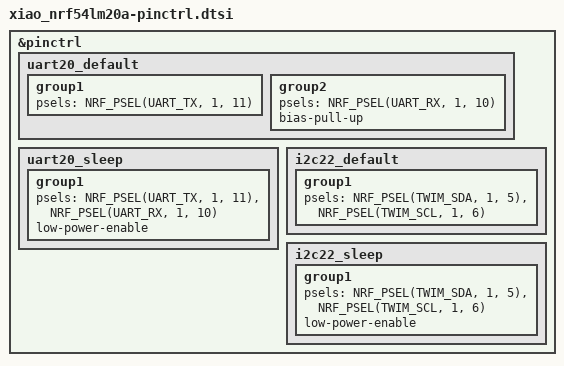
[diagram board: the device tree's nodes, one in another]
/*
 * SPDX-License-Identifier: Apache-2.0
 *
 * Pin control for the XIAO nRF54LM20A Sense. Pins verified against schematic
 * Rev V1.0 (see docs/nrf54lm20a-board.md). Only the M1 buses are defined here
 * (console UART + OLED header I2C); sensor/mic/PMIC buses are added at M3.
 */

&pinctrl {
	/* Console UART -> ATSAMD11 bridge -> USB serial. TX P1.11, RX P1.10. */
	uart20_default: uart20_default {
		group1 {
			psels = <NRF_PSEL(UART_TX, 1, 11)>;
		};
		group2 {
			psels = <NRF_PSEL(UART_RX, 1, 10)>;
			bias-pull-up;
		};
	};

	uart20_sleep: uart20_sleep {
		group1 {
			psels = <NRF_PSEL(UART_TX, 1, 11)>,
				<NRF_PSEL(UART_RX, 1, 10)>;
			low-power-enable;
		};
	};

	/*
	 * OLED bus on the XIAO header, mapped for NEAT SINGLE-EDGE WIRING.
	 * The right edge of the board runs (top->bottom): 5V, GND, 3V3, D10, D9,
	 * D8, D7. Putting SCL on D10 (P1.06) and SDA on D9 (P1.05) makes the four
	 * OLED wires land on four consecutive pads -- GND, 3V3, D10, D9 -- so a
	 * GND/VCC/SCL/SDA module solders straight down with no crossing wires.
	 * (The board's "standard" XIAO I2C pins are D4/D5; this variant repurposes
	 * the header I2C solely for the OLED, hence the wiring-driven remap.)
	 */
	i2c22_default: i2c22_default {
		group1 {
			psels = <NRF_PSEL(TWIM_SDA, 1, 5)>,   /* D9  P1.05 */
				<NRF_PSEL(TWIM_SCL, 1, 6)>;   /* D10 P1.06 */
		};
	};

	i2c22_sleep: i2c22_sleep {
		group1 {
			psels = <NRF_PSEL(TWIM_SDA, 1, 5)>,
				<NRF_PSEL(TWIM_SCL, 1, 6)>;
			low-power-enable;
		};
	};
};
